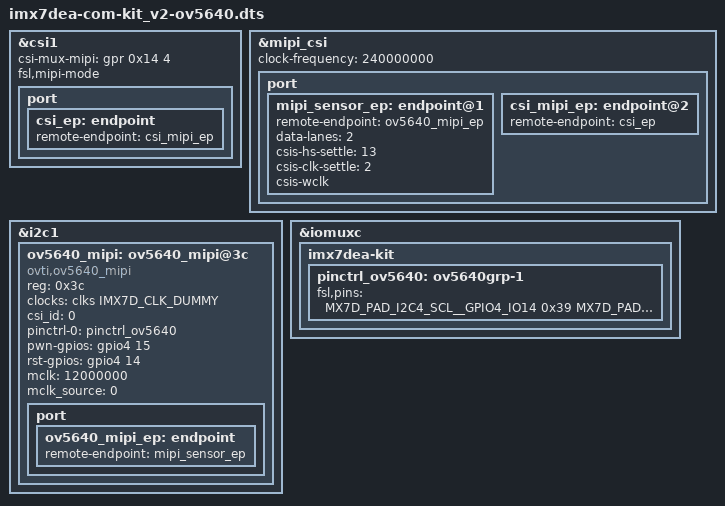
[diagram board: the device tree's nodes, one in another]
/*
 * Copyright (C) 2018 Embedded Artists AB
 *
 * This program is free software; you can redistribute it and/or modify
 * it under the terms of the GNU General Public License version 2 as
 * published by the Free Software Foundation.
 */

#include "imx7dea-com-kit_v2.dts"

&csi1 {
	csi-mux-mipi = <&gpr 0x14 4>;
	fsl,mipi-mode;
	status = "okay";

	port {
		csi_ep: endpoint {
			remote-endpoint = <&csi_mipi_ep>;
		};
	};
};

&mipi_csi {
	clock-frequency = <240000000>;
	status = "okay";
	port {
		mipi_sensor_ep: endpoint@1 {
			remote-endpoint = <&ov5640_mipi_ep>;
			data-lanes = <2>;
			csis-hs-settle = <13>;
			csis-clk-settle = <2>;
			csis-wclk;
		};

		csi_mipi_ep: endpoint@2 {
			remote-endpoint = <&csi_ep>;
		};
	};
};

&i2c1 {

        ov5640_mipi: ov5640_mipi@3c {
                compatible = "ovti,ov5640_mipi";
                reg = <0x3c>;
                clocks = <&clks IMX7D_CLK_DUMMY>;
                clock-names = "csi_mclk";
                csi_id = <0>;
                pinctrl-names = "default";
                pinctrl-0 = <&pinctrl_ov5640>;
                pwn-gpios = <&gpio4 15 GPIO_ACTIVE_HIGH>;
                rst-gpios = <&gpio4 14 GPIO_ACTIVE_HIGH>;
                mclk = <12000000>;
                mclk_source = <0>;
                port {
                        ov5640_mipi_ep: endpoint {
                                remote-endpoint = <&mipi_sensor_ep>;
                        };
                };
        };
};

&iomuxc {

        imx7dea-kit {
		pinctrl_ov5640: ov5640grp-1 {
			fsl,pins = <
				MX7D_PAD_I2C4_SCL__GPIO4_IO14           0x39
				MX7D_PAD_I2C4_SDA__GPIO4_IO15           0x39
			>;
		};
        };
};

